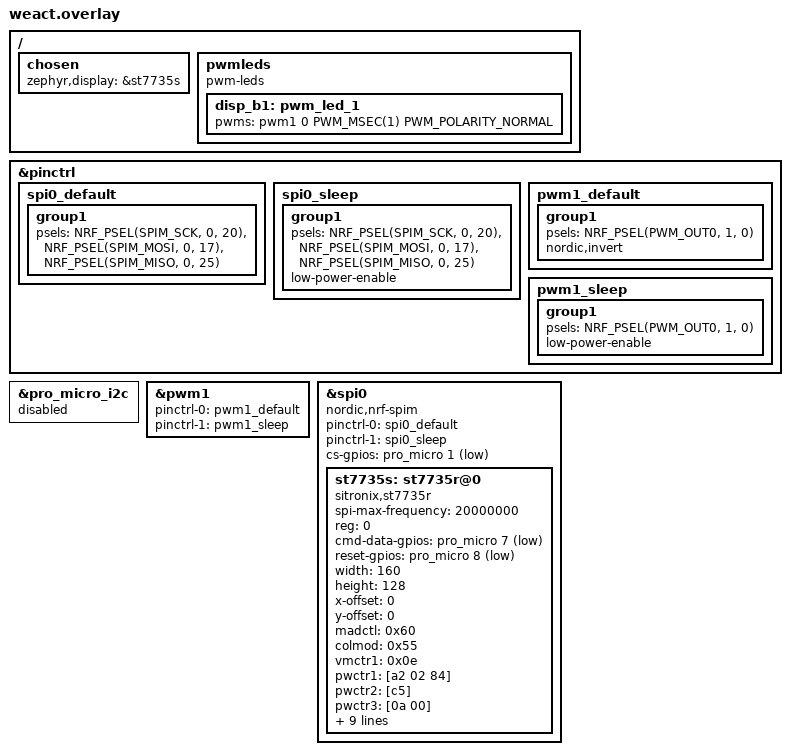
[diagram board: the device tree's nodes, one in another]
/ {
    chosen {
        zephyr,display = &st7735s;
    };

    pwmleds {
        compatible = "pwm-leds";
        disp_b1: pwm_led_1 {
            pwms = <&pwm1 0 PWM_MSEC(1) PWM_POLARITY_NORMAL>;
        };
    };
};

&pinctrl {
    spi0_default: spi0_default {
        group1 {
            psels = <NRF_PSEL(SPIM_SCK, 0, 20)>,
                <NRF_PSEL(SPIM_MOSI, 0, 17)>,
                <NRF_PSEL(SPIM_MISO, 0, 25)>;
        };
    };
    spi0_sleep: spi0_sleep {
        group1 {
            psels = <NRF_PSEL(SPIM_SCK, 0, 20)>,
                <NRF_PSEL(SPIM_MOSI, 0, 17)>,
                <NRF_PSEL(SPIM_MISO, 0, 25)>;
            low-power-enable;
        };
    };

    pwm1_default: pwm1_default {
        group1 {
            psels = <NRF_PSEL(PWM_OUT0, 1, 0)>;
            nordic,invert;
        };
    };

    pwm1_sleep: pwm1_sleep {
        group1 {
            psels = <NRF_PSEL(PWM_OUT0, 1, 0)>;
            low-power-enable;
        };
    };
};

&pro_micro_i2c {
    status = "disabled";
};

&pwm1 {
    status = "okay";
    pinctrl-0 = <&pwm1_default>;
    pinctrl-1 = <&pwm1_sleep>;
    pinctrl-names = "default", "sleep";
};

// https://github.com/zephyrproject-rtos/zephyr/blob/zephyr-v3.5.0/boards/shields/st7735r/st7735r_ada_160x128.overlay
board_spi: &spi0 {
    status = "okay";
    compatible = "nordic,nrf-spim";
    pinctrl-0 = <&spi0_default>;
    pinctrl-1 = <&spi0_sleep>;
    pinctrl-names = "default", "sleep";
    cs-gpios = <&pro_micro 1 GPIO_ACTIVE_LOW>;

    st7735s: st7735r@0 {
        compatible = "sitronix,st7735r";
        spi-max-frequency = <20000000>;
        reg = <0>;
        cmd-data-gpios = <&pro_micro 7 GPIO_ACTIVE_LOW>;
        reset-gpios = <&pro_micro 8  GPIO_ACTIVE_LOW>;
        width = <160>;
        height = <128>;
        x-offset = <0>;
        y-offset = <0>;
        madctl = <0x60>;
        colmod = <0x55>;
        vmctr1 = <0x0e>;
        pwctr1 = [a2 02 84];
        pwctr2 = [c5];
        pwctr3 = [0a 00];
        pwctr4 = [8a 2a];
        pwctr5 = [8a ee];
        frmctr1 = [01 2c 2d];
        frmctr2 = [01 2c 2d];
        frmctr3 = [01 2c 2d 01 2c 2d];
        gamctrp1 = [02 1c 07 12 37 32 29 2d 29 25 2b 39 00 01 03 10];
        gamctrn1 = [03 1d 07 06 2e 2c 29 2d 2e 2e 37 3f 00 00 02 10];
    };
};
